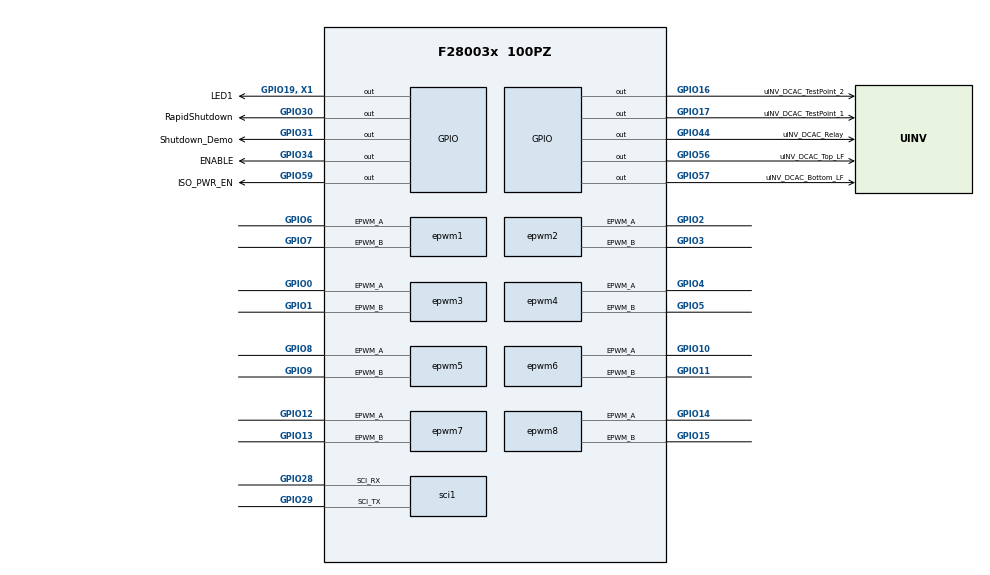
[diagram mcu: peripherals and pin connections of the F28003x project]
/**
 * @cliArgs --device "F28003x" --package "100PZ" --part "F28003x_100PZ" --context "system" --product "C2000WARE@5.02.00.00"
 * @versions {"tool":"1.20.0+3562"}
 */

/**
 * Import the modules used in this configuration.
 */
const adc              = scripting.addModule("/driverlib/adc.js", {}, false);
const adc1             = adc.addInstance();
const adc2             = adc.addInstance();
const adc3             = adc.addInstance();
const analog           = scripting.addModule("/driverlib/analog.js", {}, false);
const analog1          = analog.addInstance();
const asysctl          = scripting.addModule("/driverlib/asysctl.js");
const clb              = scripting.addModule("/driverlib/clb.js", {}, false);
const clb1             = clb.addInstance();
const cmpss            = scripting.addModule("/driverlib/cmpss.js", {}, false);
const cmpss1           = cmpss.addInstance();
const cmpss2           = cmpss.addInstance();
const device_support   = scripting.addModule("/driverlib/device_support.js");
const ecap             = scripting.addModule("/driverlib/ecap.js", {}, false);
const ecap1            = ecap.addInstance();
const epwm             = scripting.addModule("/driverlib/epwm.js", {}, false);
const epwm1            = epwm.addInstance();
const epwm2            = epwm.addInstance();
const epwm3            = epwm.addInstance();
const epwm4            = epwm.addInstance();
const epwm5            = epwm.addInstance();
const epwm6            = epwm.addInstance();
const epwm7            = epwm.addInstance();
const epwm8            = epwm.addInstance();
const epwmxbar         = scripting.addModule("/driverlib/epwmxbar.js", {}, false);
const epwmxbar1        = epwmxbar.addInstance();
const epwmxbar2        = epwmxbar.addInstance();
const epwmxbar3        = epwmxbar.addInstance();
const gpio             = scripting.addModule("/driverlib/gpio.js", {}, false);
const gpio1            = gpio.addInstance();
const gpio2            = gpio.addInstance();
const gpio3            = gpio.addInstance();
const gpio4            = gpio.addInstance();
const gpio5            = gpio.addInstance();
const gpio6            = gpio.addInstance();
const gpio7            = gpio.addInstance();
const gpio8            = gpio.addInstance();
const gpio9            = gpio.addInstance();
const gpio10           = gpio.addInstance();
const inputxbar_input  = scripting.addModule("/driverlib/inputxbar_input.js", {}, false);
const inputxbar_input1 = inputxbar_input.addInstance();
const inputxbar_input2 = inputxbar_input.addInstance();
const inputxbar_input3 = inputxbar_input.addInstance();
const inputxbar_input4 = inputxbar_input.addInstance();
const sci              = scripting.addModule("/driverlib/sci.js", {}, false);
const sci1             = sci.addInstance();
const sync             = scripting.addModule("/driverlib/sync.js");
const sysctl           = scripting.addModule("/driverlib/sysctl.js");
const CMD              = scripting.addModule("/utilities/cmd_tool/cmd_syscfg/source/CMD");
const CMD1             = CMD.addInstance();

/**
 * Write custom configuration values to the imported modules.
 */
adc1.$name                       = "ADC_A";
adc1.soc0IndependentNameMode     = true;
adc1.soc0Channel                 = "ADC_CH_ADCIN6";
adc1.soc0InputCapacitance        = 300;
adc1.soc0InputResistance         = 300;
adc1.soc0UseCalculatedSampleTime = true;
adc1.soc1InputCapacitance        = 300;
adc1.soc1InputResistance         = 300;
adc1.soc1UseCalculatedSampleTime = true;
adc1.soc1IndependentNameMode     = true;
adc1.soc2IndependentNameMode     = true;
adc1.soc3IndependentNameMode     = true;
adc1.soc2InputCapacitance        = 300;
adc1.soc2InputResistance         = 300;
adc1.soc3InputCapacitance        = 300;
adc1.soc3InputResistance         = 300;
adc1.soc3UseCalculatedSampleTime = true;
adc1.soc2UseCalculatedSampleTime = true;
adc1.interruptPulseMode          = "ADC_PULSE_END_OF_CONV";
adc1.soc4IndependentNameMode     = true;
adc1.interrupt1SOCSource         = "ADC_SOC_NUMBER3";
adc1.soc0Name                    = "SOC_BOOST1_CS1";
adc1.soc0Trigger                 = "ADC_TRIGGER_EPWM4_SOCA";
adc1.soc1Name                    = "SOC_BOOST1_CS2";
adc1.soc1Channel                 = "ADC_CH_ADCIN6";
adc1.soc1Trigger                 = "ADC_TRIGGER_EPWM4_SOCB";
adc1.soc2Name                    = "SOC_BOOST1_VS";
adc1.soc2Channel                 = "ADC_CH_ADCIN5";
adc1.soc2Trigger                 = "ADC_TRIGGER_EPWM4_SOCB";
adc1.soc3Name                    = "SOC_BOOST2_CS1";
adc1.soc3Channel                 = "ADC_CH_ADCIN4";
adc1.soc3Trigger                 = "ADC_TRIGGER_EPWM2_SOCA";
adc1.enabledSOCs                 = ["ADC_SOC_NUMBER0","ADC_SOC_NUMBER1","ADC_SOC_NUMBER2","ADC_SOC_NUMBER3","ADC_SOC_NUMBER4","ADC_SOC_NUMBER5"];
adc1.soc4Name                    = "SOC_BOOST2_CS2";
adc1.soc4Channel                 = "ADC_CH_ADCIN4";
adc1.soc4Trigger                 = "ADC_TRIGGER_EPWM2_SOCB";
adc1.soc4UseCalculatedSampleTime = true;
adc1.soc4InputResistance         = 100;
adc1.soc4InputCapacitance        = 100;
adc1.soc4SampleWindow            = 12;
adc1.soc3SampleWindow            = 12;
adc1.soc2SampleWindow            = 12;
adc1.soc1SampleWindow            = 12;
adc1.soc0SampleWindow            = 12;
adc1.soc5Name                    = "SOC_BOOST2_VS";
adc1.soc5SampleWindow            = 12;
adc1.soc5Channel                 = "ADC_CH_ADCIN2";
adc1.soc5Trigger                 = "ADC_TRIGGER_EPWM2_SOCB";
adc1.soc5IndependentNameMode     = true;
adc1.adcClockPrescaler           = "ADC_CLK_DIV_2_0";

adc2.$name                       = "ADC_B";
adc2.adcBase                     = "ADCB_BASE";
adc2.soc0IndependentNameMode     = true;
adc2.soc1IndependentNameMode     = true;
adc2.soc0Channel                 = "ADC_CH_ADCIN3";
adc2.soc0InputCapacitance        = 300;
adc2.soc0InputResistance         = 300;
adc2.soc0UseCalculatedSampleTime = true;
adc2.soc1InputCapacitance        = 300;
adc2.soc1InputResistance         = 300;
adc2.soc1UseCalculatedSampleTime = true;
adc2.soc2IndependentNameMode     = true;
adc2.soc3IndependentNameMode     = true;
adc2.soc2InputCapacitance        = 300;
adc2.soc2InputResistance         = 300;
adc2.soc2UseCalculatedSampleTime = true;
adc2.soc3InputCapacitance        = 300;
adc2.soc3InputResistance         = 300;
adc2.soc3UseCalculatedSampleTime = true;
adc2.soc4IndependentNameMode     = true;
adc2.soc4InputResistance         = 300;
adc2.soc4UseCalculatedSampleTime = true;
adc2.soc4InputCapacitance        = 300;
adc2.soc5IndependentNameMode     = true;
adc2.soc5InputCapacitance        = 100000;
adc2.soc5InputResistance         = 300;
adc2.soc5UseCalculatedSampleTime = true;
adc2.interruptPulseMode          = "ADC_PULSE_END_OF_CONV";
adc2.soc0Name                    = "SOC_BOOST3_CS1";
adc2.soc0Trigger                 = "ADC_TRIGGER_EPWM1_SOCA";
adc2.soc0SampleWindow            = 12;
adc2.soc1Name                    = "SOC_BOOST3_CS2";
adc2.soc1Channel                 = "ADC_CH_ADCIN3";
adc2.soc1Trigger                 = "ADC_TRIGGER_EPWM1_SOCB";
adc2.soc1SampleWindow            = 12;
adc2.soc2Name                    = "SOC_BOOST3_VS";
adc2.soc2Channel                 = "ADC_CH_ADCIN2";
adc2.soc2Trigger                 = "ADC_TRIGGER_EPWM1_SOCB";
adc2.soc2SampleWindow            = 12;
adc2.soc3Name                    = "SOC_BOOST4_CS1";
adc2.soc3Trigger                 = "ADC_TRIGGER_EPWM3_SOCA";
adc2.soc3SampleWindow            = 12;
adc2.soc3Channel                 = "ADC_CH_ADCIN12";
adc2.soc4Name                    = "SOC_BOOST4_CS2";
adc2.soc4Channel                 = "ADC_CH_ADCIN12";
adc2.soc4Trigger                 = "ADC_TRIGGER_EPWM3_SOCB";
adc2.soc4SampleWindow            = 12;
adc2.soc5Name                    = "SOC_BOOST4_VS";
adc2.soc5Channel                 = "ADC_CH_ADCIN4";
adc2.soc5Trigger                 = "ADC_TRIGGER_EPWM3_SOCB";
adc2.soc5SampleWindow            = 12;
adc2.enabledSOCs                 = ["ADC_SOC_NUMBER0","ADC_SOC_NUMBER1","ADC_SOC_NUMBER2","ADC_SOC_NUMBER3","ADC_SOC_NUMBER4","ADC_SOC_NUMBER5","ADC_SOC_NUMBER6","ADC_SOC_NUMBER7"];
adc2.soc6Name                    = "SOC_LLC_VS";
adc2.soc6Channel                 = "ADC_CH_ADCIN5";
adc2.soc6Trigger                 = "ADC_TRIGGER_EPWM3_SOCB";
adc2.soc6SampleWindow            = 12;
adc2.soc7Name                    = "SOC_IREF";
adc2.soc7Channel                 = "ADC_CH_ADCIN11";
adc2.soc7Trigger                 = "ADC_TRIGGER_EPWM3_SOCA";
adc2.soc7SampleWindow            = 12;
adc2.soc7IndependentNameMode     = true;
adc2.soc6IndependentNameMode     = true;
adc2.enabledInts                 = ["ADC_INT_NUMBER1"];
adc2.enableInterrupt1            = true;
adc2.interrupt1SOCSource         = "ADC_SOC_NUMBER6";
adc2.registerInterrupts          = ["1"];
adc2.adcClockPrescaler           = "ADC_CLK_DIV_2_0";
adc2.adcInt1.enableInterrupt     = true;
adc2.adcInt1.interruptHandler    = "ISR2";

adc3.$name                       = "ADC_C";
adc3.adcBase                     = "ADCC_BASE";
adc3.soc0IndependentNameMode     = true;
adc3.soc0InputCapacitance        = 300;
adc3.soc0InputResistance         = 300;
adc3.soc0UseCalculatedSampleTime = true;
adc3.soc1IndependentNameMode     = true;
adc3.soc1InputCapacitance        = 300;
adc3.soc1InputResistance         = 300;
adc3.soc1UseCalculatedSampleTime = true;
adc3.soc2IndependentNameMode     = true;
adc3.soc2InputCapacitance        = 300;
adc3.soc2InputResistance         = 300;
adc3.soc2UseCalculatedSampleTime = true;
adc3.soc3IndependentNameMode     = true;
adc3.soc3InputCapacitance        = 300;
adc3.soc3InputResistance         = 300;
adc3.soc3UseCalculatedSampleTime = true;
adc3.soc4IndependentNameMode     = true;
adc3.soc4InputResistance         = 10000;
adc3.soc4InputCapacitance        = 100000;
adc3.enableInterrupt1            = true;
adc3.soc5IndependentNameMode     = true;
adc3.soc5SampleWindow            = 100;
adc3.interrupt1SOCSource         = "ADC_SOC_NUMBER5";
adc3.soc0Trigger                 = "ADC_TRIGGER_EPWM8_SOCA";
adc3.soc0SampleWindow            = 12;
adc3.soc1SampleWindow            = 12;
adc3.soc2SampleWindow            = 12;
adc3.soc1Trigger                 = "ADC_TRIGGER_EPWM8_SOCA";
adc3.soc2Trigger                 = "ADC_TRIGGER_EPWM8_SOCB";
adc3.soc3Trigger                 = "ADC_TRIGGER_EPWM8_SOCB";
adc3.soc3SampleWindow            = 12;
adc3.soc4Trigger                 = "ADC_TRIGGER_EPWM8_SOCA";
adc3.soc4SampleWindow            = 12;
adc3.soc5Trigger                 = "ADC_TRIGGER_EPWM8_SOCB";
adc3.enabledSOCs                 = ["ADC_SOC_NUMBER0","ADC_SOC_NUMBER1","ADC_SOC_NUMBER2","ADC_SOC_NUMBER3","ADC_SOC_NUMBER4","ADC_SOC_NUMBER5","ADC_SOC_NUMBER6"];
adc3.soc6Name                    = "SOC_TEMP";
adc3.soc6IndependentNameMode     = true;
adc3.soc6Channel                 = "ADC_CH_ADCIN1";
adc3.soc6SampleWindow            = 12;
adc3.interrupt2SOCSource         = "ADC_SOC_NUMBER4";
adc3.enableInterrupt2            = true;
adc3.interruptPulseMode          = "ADC_PULSE_END_OF_CONV";
adc3.soc0Channel                 = "ADC_CH_ADCIN5";
adc3.soc1Channel                 = "ADC_CH_ADCIN3";
adc3.soc2Channel                 = "ADC_CH_ADCIN5";
adc3.soc3Channel                 = "ADC_CH_ADCIN3";
adc3.soc0Name                    = "SOC_DC_BUS_CS1";
adc3.soc1Name                    = "SOC_AC_CS1";
adc3.soc2Name                    = "SOC_DC_BUS_CS2";
adc3.soc3Name                    = "SOC_AC_CS2";
adc3.soc4Name                    = "SOC_AC_VS";
adc3.soc5Name                    = "SOC_DC_BUS_VS";
adc3.enabledInts                 = ["ADC_INT_NUMBER1"];
adc3.registerInterrupts          = ["1"];
adc3.adcClockPrescaler           = "ADC_CLK_DIV_2_0";
adc3.soc5Channel                 = "ADC_CH_ADCIN11";
adc3.soc4Channel                 = "ADC_CH_ADCIN7";
adc3.adcInt1.enableInterrupt     = true;
adc3.adcInt1.interruptHandler    = "ISR1";

asysctl.enableTemperatureSensor = true;
asysctl.analogReference         = "INTERNAL";
asysctl.analogReferenceVoltage  = "1P65";

clb1.$name     = "myCLB0";
clb1.enableCLB = true;

cmpss1.cmpssBase           = "CMPSS4_BASE";
cmpss1.enableModule        = true;
cmpss1.asysCMPHPMXSELValue = "1";
cmpss1.asysCMPLPMXSELValue = "1";
cmpss1.lowCompInvert       = true;
cmpss1.dacValHigh          = 3500;
cmpss1.dacValLow           = 500;
cmpss1.$name               = "myCMPSS";

cmpss2.$name               = "CMPSS_SR";
cmpss2.cmpssBase           = "CMPSS2_BASE";
cmpss2.asysCMPHPMXSELValue = "2";
cmpss2.asysCMPLPMXSELValue = "2";
cmpss2.enableModule        = true;
cmpss2.enableBlanking      = true;
cmpss2.configBlanking      = "7";
cmpss2.configLatchLow      = true;
cmpss2.configLatchHigh     = true;
cmpss2.latchResetHigh      = true;
cmpss2.latchResetLow       = true;
cmpss2.lowCompInvert       = true;
cmpss2.initFilterHigh      = true;
cmpss2.initFilterLow       = true;
cmpss2.lowCTRIP            = "CMPSS_TRIP_FILTER";
cmpss2.highCTRIP           = "CMPSS_TRIP_FILTER";
cmpss2.dacValHigh          = 2000;
cmpss2.dacValLow           = 2096;
cmpss2.sampleWindowLow     = 7;
cmpss2.thresholdLow        = 5;
cmpss2.sampleWindowHigh    = 7;
cmpss2.thresholdHigh       = 5;

cmpss1.analog            = analog1;
analog1.$name            = "myANALOGPinMux0";
adc1.analog              = analog1;
adc3.analog              = analog1;
adc2.analog              = analog1;
analog1.useCase          = "CUSTOM";
cmpss2.analog            = analog1;
analog1.useInterfacePins = ["A0/B15/C15/DACA_OUT","A1/B7/DACB_OUT","A10/B1/C10","A12, C5","A2/B6/C9","A3, C7/B9","A4/B8","A5","A6","A9","B0/C11","B11","B2/C6","B3/VDAC","B4/C8","B5","C1","C2/B12","C3/A7"];

ecap1.$name                  = "myECAP0";
ecap1.interruptSourceCapture = ["ECAP_ISR_SOURCE_CAPTURE_EVENT_4"];
ecap1.eventStop              = "ECAP_EVENT_4";
ecap1.resetCounters          = true;
ecap1.eventOnePolarity       = "ECAP_EVNT_FALLING_EDGE";
ecap1.eventThreePolarity     = "ECAP_EVNT_FALLING_EDGE";
ecap1.counterResetOnEvent    = ["ECAP_EVENT_4"];
ecap1.enableLoadCounter      = true;
ecap1.captureMode            = "ECAP_ONE_SHOT_CAPTURE_MODE";
ecap1.ecapInput              = "ECAP_INPUT_INPUTXBAR1";

epwm1.$name                                                      = "BOOST1";
epwm1.epwmDeadband_enableFED                                     = true;
epwm1.epwmDeadband_enableRED                                     = true;
epwm1.epwmDeadband_polarityFED                                   = "EPWM_DB_POLARITY_ACTIVE_LOW";
epwm1.epwmActionQualifier_EPWM_AQ_OUTPUT_A_ON_TIMEBASE_UP_CMPA   = "EPWM_AQ_OUTPUT_LOW";
epwm1.epwmTimebase_hsClockDiv                                    = "EPWM_HSCLOCK_DIVIDER_1";
epwm1.epwmTimebase_emulationMode                                 = "EPWM_EMULATION_FREE_RUN";
epwm1.epwmEventTrigger_EPWM_SOC_B_triggerEnable                  = true;
epwm1.epwmEventTrigger_EPWM_SOC_A_triggerEnable                  = true;
epwm1.epwmActionQualifier_EPWM_AQ_OUTPUT_A_ON_TIMEBASE_ZERO      = "EPWM_AQ_OUTPUT_HIGH";
epwm1.epwmActionQualifier_EPWM_AQ_OUTPUT_B_ON_TIMEBASE_ZERO      = "EPWM_AQ_OUTPUT_HIGH";
epwm1.epwmDeadband_inputFED                                      = "EPWM_DB_INPUT_EPWMB";
epwm1.epwmTripZone_EPWM_TZ_ACTION_EVENT_TZA                      = "EPWM_TZ_ACTION_LOW";
epwm1.epwmTripZone_EPWM_TZ_ACTION_EVENT_TZB                      = "EPWM_TZ_ACTION_LOW";
epwm1.epwmTripZone_EPWM_TZ_ACTION_EVENT_DCAEVT1                  = "EPWM_TZ_ACTION_LOW";
epwm1.epwmTripZone_EPWM_TZ_ACTION_EVENT_DCAEVT2                  = "EPWM_TZ_ACTION_LOW";
epwm1.epwmTripZone_EPWM_TZ_ACTION_EVENT_DCBEVT1                  = "EPWM_TZ_ACTION_LOW";
epwm1.epwmTripZone_EPWM_TZ_ACTION_EVENT_DCBEVT2                  = "EPWM_TZ_ACTION_LOW";
epwm1.epwmEventTrigger_EPWM_SOC_A_triggerEventPrescalar          = "6";
epwm1.epwmEventTrigger_EPWM_SOC_B_triggerEventPrescalar          = "6";
epwm1.epwmDeadband_delayRED                                      = 2;
epwm1.epwmDeadband_delayFED                                      = 2;
epwm1.epwmTimebase_phaseEnable                                   = true;
epwm1.epwmTimebase_syncOutPulseMode                              = ["EPWM_SYNC_OUT_PULSE_ON_SOFTWARE"];
epwm1.epwmTimebase_counterMode                                   = "EPWM_COUNTER_MODE_UP_DOWN";
epwm1.epwmTimebase_phaseShift                                    = 2;
epwm1.epwmTimebase_period                                        = 250;
epwm1.epwmEventTrigger_EPWM_SOC_A_triggerSource                  = "EPWM_SOC_TBCTR_ZERO";
epwm1.epwmEventTrigger_EPWM_SOC_B_triggerSource                  = "EPWM_SOC_TBCTR_PERIOD";
epwm1.epwmActionQualifier_EPWM_AQ_OUTPUT_A_ON_TIMEBASE_PERIOD    = "EPWM_AQ_OUTPUT_LOW";
epwm1.epwmActionQualifier_EPWM_AQ_OUTPUT_A_ON_TIMEBASE_DOWN_CMPA = "EPWM_AQ_OUTPUT_HIGH";
epwm1.epwmActionQualifier_EPWM_AQ_OUTPUT_B_ON_TIMEBASE_PERIOD    = "EPWM_AQ_OUTPUT_LOW";
epwm1.epwmActionQualifier_EPWM_AQ_OUTPUT_B_ON_TIMEBASE_UP_CMPB   = "EPWM_AQ_OUTPUT_LOW";
epwm1.epwmActionQualifier_EPWM_AQ_OUTPUT_B_ON_TIMEBASE_DOWN_CMPB = "EPWM_AQ_OUTPUT_HIGH";
epwm1.epwmTimebase_counterModeAfterSync                          = "EPWM_COUNT_MODE_UP_AFTER_SYNC";
epwm1.epwmTimebase_syncInPulseSource                             = "EPWM_SYNC_IN_PULSE_SRC_SYNCOUT_EPWM8";
epwm1.epwm.epwm_aPin.$assign                                     = "GPIO6";
epwm1.epwm.epwm_bPin.$assign                                     = "GPIO7";

epwm2.$name                                                      = "BOOST2";
epwm2.epwmDeadband_enableFED                                     = true;
epwm2.epwmDeadband_enableRED                                     = true;
epwm2.epwmDeadband_polarityFED                                   = "EPWM_DB_POLARITY_ACTIVE_LOW";
epwm2.epwmActionQualifier_EPWM_AQ_OUTPUT_A_ON_TIMEBASE_UP_CMPA   = "EPWM_AQ_OUTPUT_LOW";
epwm2.epwmTimebase_hsClockDiv                                    = "EPWM_HSCLOCK_DIVIDER_1";
epwm2.epwmTimebase_emulationMode                                 = "EPWM_EMULATION_FREE_RUN";
epwm2.epwmEventTrigger_EPWM_SOC_B_triggerEnable                  = true;
epwm2.epwmEventTrigger_EPWM_SOC_A_triggerEnable                  = true;
epwm2.epwmActionQualifier_EPWM_AQ_OUTPUT_A_ON_TIMEBASE_ZERO      = "EPWM_AQ_OUTPUT_HIGH";
epwm2.epwmActionQualifier_EPWM_AQ_OUTPUT_B_ON_TIMEBASE_ZERO      = "EPWM_AQ_OUTPUT_HIGH";
epwm2.epwmDeadband_inputFED                                      = "EPWM_DB_INPUT_EPWMB";
epwm2.epwmTripZone_EPWM_TZ_ACTION_EVENT_TZA                      = "EPWM_TZ_ACTION_LOW";
epwm2.epwmTripZone_EPWM_TZ_ACTION_EVENT_TZB                      = "EPWM_TZ_ACTION_LOW";
epwm2.epwmTripZone_EPWM_TZ_ACTION_EVENT_DCAEVT1                  = "EPWM_TZ_ACTION_LOW";
epwm2.epwmTripZone_EPWM_TZ_ACTION_EVENT_DCAEVT2                  = "EPWM_TZ_ACTION_LOW";
epwm2.epwmTripZone_EPWM_TZ_ACTION_EVENT_DCBEVT1                  = "EPWM_TZ_ACTION_LOW";
epwm2.epwmTripZone_EPWM_TZ_ACTION_EVENT_DCBEVT2                  = "EPWM_TZ_ACTION_LOW";
epwm2.epwmEventTrigger_EPWM_SOC_B_triggerEventPrescalar          = "6";
epwm2.epwmEventTrigger_EPWM_SOC_A_triggerEventPrescalar          = "6";
epwm2.epwmDeadband_delayRED                                      = 2;
epwm2.epwmDeadband_delayFED                                      = 2;
epwm2.epwmTimebase_phaseEnable                                   = true;
epwm2.epwmTimebase_period                                        = 250;
epwm2.epwmTimebase_phaseShift                                    = 2;
epwm2.epwmTimebase_counterMode                                   = "EPWM_COUNTER_MODE_UP_DOWN";
epwm2.epwmActionQualifier_EPWM_AQ_OUTPUT_A_ON_TIMEBASE_PERIOD    = "EPWM_AQ_OUTPUT_LOW";
epwm2.epwmActionQualifier_EPWM_AQ_OUTPUT_A_ON_TIMEBASE_DOWN_CMPA = "EPWM_AQ_OUTPUT_HIGH";
epwm2.epwmActionQualifier_EPWM_AQ_OUTPUT_B_ON_TIMEBASE_PERIOD    = "EPWM_AQ_OUTPUT_LOW";
epwm2.epwmActionQualifier_EPWM_AQ_OUTPUT_B_ON_TIMEBASE_UP_CMPB   = "EPWM_AQ_OUTPUT_LOW";
epwm2.epwmActionQualifier_EPWM_AQ_OUTPUT_B_ON_TIMEBASE_DOWN_CMPB = "EPWM_AQ_OUTPUT_HIGH";
epwm2.epwmEventTrigger_EPWM_SOC_A_triggerSource                  = "EPWM_SOC_TBCTR_ZERO";
epwm2.epwmEventTrigger_EPWM_SOC_B_triggerSource                  = "EPWM_SOC_TBCTR_PERIOD";
epwm2.epwmTimebase_counterModeAfterSync                          = "EPWM_COUNT_MODE_UP_AFTER_SYNC";
epwm2.epwmTimebase_syncInPulseSource                             = "EPWM_SYNC_IN_PULSE_SRC_SYNCOUT_EPWM8";
epwm2.epwm.$assign                                               = "EPWM2";
epwm2.epwm.epwm_aPin.$assign                                     = "GPIO2";
epwm2.epwm.epwm_bPin.$assign                                     = "GPIO3";

epwm3.$name                                                      = "BOOST3";
epwm3.epwmDeadband_enableFED                                     = true;
epwm3.epwmDeadband_enableRED                                     = true;
epwm3.epwmDeadband_polarityFED                                   = "EPWM_DB_POLARITY_ACTIVE_LOW";
epwm3.epwmActionQualifier_EPWM_AQ_OUTPUT_A_ON_TIMEBASE_UP_CMPA   = "EPWM_AQ_OUTPUT_LOW";
epwm3.epwmTimebase_hsClockDiv                                    = "EPWM_HSCLOCK_DIVIDER_1";
epwm3.epwmTimebase_emulationMode                                 = "EPWM_EMULATION_FREE_RUN";
epwm3.epwmEventTrigger_EPWM_SOC_B_triggerEnable                  = true;
epwm3.epwmEventTrigger_EPWM_SOC_A_triggerEnable                  = true;
epwm3.epwmActionQualifier_EPWM_AQ_OUTPUT_A_ON_TIMEBASE_ZERO      = "EPWM_AQ_OUTPUT_HIGH";
epwm3.epwmActionQualifier_EPWM_AQ_OUTPUT_B_ON_TIMEBASE_ZERO      = "EPWM_AQ_OUTPUT_HIGH";
epwm3.epwmDeadband_inputFED                                      = "EPWM_DB_INPUT_EPWMB";
epwm3.epwmTripZone_EPWM_TZ_ACTION_EVENT_TZA                      = "EPWM_TZ_ACTION_LOW";
epwm3.epwmTripZone_EPWM_TZ_ACTION_EVENT_TZB                      = "EPWM_TZ_ACTION_LOW";
epwm3.epwmTripZone_EPWM_TZ_ACTION_EVENT_DCAEVT1                  = "EPWM_TZ_ACTION_LOW";
epwm3.epwmTripZone_EPWM_TZ_ACTION_EVENT_DCAEVT2                  = "EPWM_TZ_ACTION_LOW";
epwm3.epwmTripZone_EPWM_TZ_ACTION_EVENT_DCBEVT1                  = "EPWM_TZ_ACTION_LOW";
epwm3.epwmTripZone_EPWM_TZ_ACTION_EVENT_DCBEVT2                  = "EPWM_TZ_ACTION_LOW";
epwm3.epwmEventTrigger_EPWM_SOC_B_triggerEventPrescalar          = "6";
epwm3.epwmEventTrigger_EPWM_SOC_A_triggerEventPrescalar          = "6";
epwm3.epwmDeadband_delayRED                                      = 2;
epwm3.epwmDeadband_delayFED                                      = 2;
epwm3.epwmTimebase_phaseEnable                                   = true;
epwm3.epwmTimebase_period                                        = 250;
epwm3.epwmTimebase_phaseShift                                    = 2;
epwm3.epwmTimebase_counterMode                                   = "EPWM_COUNTER_MODE_UP_DOWN";
epwm3.epwmActionQualifier_EPWM_AQ_OUTPUT_A_ON_TIMEBASE_PERIOD    = "EPWM_AQ_OUTPUT_LOW";
epwm3.epwmActionQualifier_EPWM_AQ_OUTPUT_A_ON_TIMEBASE_DOWN_CMPA = "EPWM_AQ_OUTPUT_HIGH";
epwm3.epwmActionQualifier_EPWM_AQ_OUTPUT_B_ON_TIMEBASE_PERIOD    = "EPWM_AQ_OUTPUT_LOW";
epwm3.epwmActionQualifier_EPWM_AQ_OUTPUT_B_ON_TIMEBASE_UP_CMPB   = "EPWM_AQ_OUTPUT_LOW";
epwm3.epwmActionQualifier_EPWM_AQ_OUTPUT_B_ON_TIMEBASE_DOWN_CMPB = "EPWM_AQ_OUTPUT_HIGH";
epwm3.epwmEventTrigger_EPWM_SOC_A_triggerSource                  = "EPWM_SOC_TBCTR_ZERO";
epwm3.epwmEventTrigger_EPWM_SOC_B_triggerSource                  = "EPWM_SOC_TBCTR_PERIOD";
epwm3.epwmTimebase_syncInPulseSource                             = "EPWM_SYNC_IN_PULSE_SRC_SYNCOUT_EPWM8";
epwm3.epwm.$assign                                               = "EPWM1";
epwm3.epwm.epwm_aPin.$assign                                     = "GPIO0";
epwm3.epwm.epwm_bPin.$assign                                     = "GPIO1";

epwm4.$name                                                      = "BOOST4";
epwm4.epwmDeadband_enableFED                                     = true;
epwm4.epwmDeadband_enableRED                                     = true;
epwm4.epwmDeadband_polarityFED                                   = "EPWM_DB_POLARITY_ACTIVE_LOW";
epwm4.epwmActionQualifier_EPWM_AQ_OUTPUT_A_ON_TIMEBASE_UP_CMPA   = "EPWM_AQ_OUTPUT_LOW";
epwm4.epwmTimebase_hsClockDiv                                    = "EPWM_HSCLOCK_DIVIDER_1";
epwm4.epwmTimebase_emulationMode                                 = "EPWM_EMULATION_FREE_RUN";
epwm4.epwmEventTrigger_EPWM_SOC_B_triggerEnable                  = true;
epwm4.epwmEventTrigger_EPWM_SOC_A_triggerEnable                  = true;
epwm4.epwmActionQualifier_EPWM_AQ_OUTPUT_A_ON_TIMEBASE_ZERO      = "EPWM_AQ_OUTPUT_HIGH";
epwm4.epwmActionQualifier_EPWM_AQ_OUTPUT_B_ON_TIMEBASE_ZERO      = "EPWM_AQ_OUTPUT_HIGH";
epwm4.epwmDeadband_inputFED                                      = "EPWM_DB_INPUT_EPWMB";
epwm4.epwmTripZone_EPWM_TZ_ACTION_EVENT_TZA                      = "EPWM_TZ_ACTION_LOW";
epwm4.epwmTripZone_EPWM_TZ_ACTION_EVENT_TZB                      = "EPWM_TZ_ACTION_LOW";
epwm4.epwmTripZone_EPWM_TZ_ACTION_EVENT_DCAEVT1                  = "EPWM_TZ_ACTION_LOW";
epwm4.epwmTripZone_EPWM_TZ_ACTION_EVENT_DCAEVT2                  = "EPWM_TZ_ACTION_LOW";
epwm4.epwmTripZone_EPWM_TZ_ACTION_EVENT_DCBEVT1                  = "EPWM_TZ_ACTION_LOW";
epwm4.epwmTripZone_EPWM_TZ_ACTION_EVENT_DCBEVT2                  = "EPWM_TZ_ACTION_LOW";
epwm4.epwmEventTrigger_EPWM_SOC_A_triggerEventPrescalar          = "6";
epwm4.epwmEventTrigger_EPWM_SOC_B_triggerEventPrescalar          = "6";
epwm4.epwmDeadband_delayRED                                      = 2;
epwm4.epwmDeadband_delayFED                                      = 2;
epwm4.epwmTimebase_phaseEnable                                   = true;
epwm4.epwmTimebase_period                                        = 250;
epwm4.epwmTimebase_counterMode                                   = "EPWM_COUNTER_MODE_UP_DOWN";
epwm4.epwmTimebase_phaseShift                                    = 2;
epwm4.epwmActionQualifier_EPWM_AQ_OUTPUT_A_ON_TIMEBASE_PERIOD    = "EPWM_AQ_OUTPUT_LOW";
epwm4.epwmActionQualifier_EPWM_AQ_OUTPUT_A_ON_TIMEBASE_DOWN_CMPA = "EPWM_AQ_OUTPUT_HIGH";
epwm4.epwmActionQualifier_EPWM_AQ_OUTPUT_B_ON_TIMEBASE_PERIOD    = "EPWM_AQ_OUTPUT_LOW";
epwm4.epwmActionQualifier_EPWM_AQ_OUTPUT_B_ON_TIMEBASE_UP_CMPB   = "EPWM_AQ_OUTPUT_LOW";
epwm4.epwmActionQualifier_EPWM_AQ_OUTPUT_B_ON_TIMEBASE_DOWN_CMPB = "EPWM_AQ_OUTPUT_HIGH";
epwm4.epwmEventTrigger_EPWM_SOC_A_triggerSource                  = "EPWM_SOC_TBCTR_ZERO";
epwm4.epwmEventTrigger_EPWM_SOC_B_triggerSource                  = "EPWM_SOC_TBCTR_PERIOD";
epwm4.epwmTimebase_syncInPulseSource                             = "EPWM_SYNC_IN_PULSE_SRC_SYNCOUT_EPWM8";
epwm4.epwm.$assign                                               = "EPWM3";
epwm4.epwm.epwm_aPin.$assign                                     = "GPIO4";
epwm4.epwm.epwm_bPin.$assign                                     = "GPIO5";

epwm5.$name                                                      = "LLC1";
epwm5.copyUse                                                    = true;
epwm5.copyFrom                                                   = "BOOST1";
epwm5.epwmActionQualifier_EPWM_AQ_OUTPUT_A_ON_TIMEBASE_UP_CMPA   = "EPWM_AQ_OUTPUT_LOW";
epwm5.epwmDeadband_polarityFED                                   = "EPWM_DB_POLARITY_ACTIVE_LOW";
epwm5.epwmDeadband_enableRED                                     = true;
epwm5.epwmDeadband_enableFED                                     = true;
epwm5.epwmTimebase_hsClockDiv                                    = "EPWM_HSCLOCK_DIVIDER_1";
epwm5.epwmActionQualifier_EPWM_AQ_OUTPUT_A_ON_TIMEBASE_ZERO      = "EPWM_AQ_OUTPUT_HIGH";
epwm5.epwmTimebase_emulationMode                                 = "EPWM_EMULATION_FREE_RUN";
epwm5.epwmTimebase_syncOutPulseMode                              = ["EPWM_SYNC_OUT_PULSE_ON_CNTR_ZERO"];
epwm5.epwmDeadband_delayRED                                      = 3;
epwm5.epwmDeadband_delayFED                                      = 3;
epwm5.epwmTimebase_syncInPulseSource                             = "EPWM_SYNC_IN_PULSE_SRC_DISABLE";
epwm5.epwmTimebase_counterMode                                   = "EPWM_COUNTER_MODE_UP_DOWN";
epwm5.epwmActionQualifier_EPWM_AQ_OUTPUT_A_ON_TIMEBASE_DOWN_CMPA = "EPWM_AQ_OUTPUT_HIGH";
epwm5.epwmActionQualifier_EPWM_AQ_OUTPUT_A_ON_TIMEBASE_PERIOD    = "EPWM_AQ_OUTPUT_LOW";
epwm5.epwmTripZone_EPWM_TZ_ACTION_EVENT_TZA                      = "EPWM_TZ_ACTION_LOW";
epwm5.epwmTripZone_EPWM_TZ_ACTION_EVENT_TZB                      = "EPWM_TZ_ACTION_LOW";
epwm5.epwmTripZone_EPWM_TZ_ACTION_EVENT_DCAEVT1                  = "EPWM_TZ_ACTION_LOW";
epwm5.epwmTripZone_EPWM_TZ_ACTION_EVENT_DCAEVT2                  = "EPWM_TZ_ACTION_LOW";
epwm5.epwmTripZone_EPWM_TZ_ACTION_EVENT_DCBEVT1                  = "EPWM_TZ_ACTION_LOW";
epwm5.epwmTripZone_EPWM_TZ_ACTION_EVENT_DCBEVT2                  = "EPWM_TZ_ACTION_LOW";
epwm5.epwmTimebase_period                                        = 120;
epwm5.epwm.$assign                                               = "EPWM5";
epwm5.epwm.epwm_aPin.$assign                                     = "GPIO8";
epwm5.epwm.epwm_bPin.$assign                                     = "GPIO9";

epwm6.$name                                                      = "LLC2";
epwm6.copyUse                                                    = true;
epwm6.copyFrom                                                   = "LLC1";
epwm6.epwmDeadband_polarityFED                                   = "EPWM_DB_POLARITY_ACTIVE_LOW";
epwm6.epwmDeadband_enableRED                                     = true;
epwm6.epwmDeadband_enableFED                                     = true;
epwm6.epwmTimebase_hsClockDiv                                    = "EPWM_HSCLOCK_DIVIDER_1";
epwm6.epwmTimebase_phaseEnable                                   = true;
epwm6.epwmActionQualifier_EPWM_AQ_OUTPUT_A_ON_TIMEBASE_ZERO      = "EPWM_AQ_OUTPUT_HIGH";
epwm6.epwmActionQualifier_EPWM_AQ_OUTPUT_A_ON_TIMEBASE_UP_CMPA   = "EPWM_AQ_OUTPUT_LOW";
epwm6.epwmTimebase_emulationMode                                 = "EPWM_EMULATION_FREE_RUN";
epwm6.epwmTimebase_syncInPulseSource                             = "EPWM_SYNC_IN_PULSE_SRC_SYNCOUT_EPWM5";
epwm6.epwmDeadband_delayRED                                      = 3;
epwm6.epwmDeadband_delayFED                                      = 3;
epwm6.epwmTimebase_period                                        = 120;
epwm6.epwmTimebase_counterMode                                   = "EPWM_COUNTER_MODE_UP_DOWN";
epwm6.epwmTimebase_phaseShift                                    = 120;
epwm6.epwmActionQualifier_EPWM_AQ_OUTPUT_A_ON_TIMEBASE_DOWN_CMPA = "EPWM_AQ_OUTPUT_HIGH";
epwm6.epwmActionQualifier_EPWM_AQ_OUTPUT_A_ON_TIMEBASE_PERIOD    = "EPWM_AQ_OUTPUT_LOW";
epwm6.epwmTripZone_EPWM_TZ_ACTION_EVENT_TZA                      = "EPWM_TZ_ACTION_LOW";
epwm6.epwmTripZone_EPWM_TZ_ACTION_EVENT_TZB                      = "EPWM_TZ_ACTION_LOW";
epwm6.epwmTripZone_EPWM_TZ_ACTION_EVENT_DCAEVT1                  = "EPWM_TZ_ACTION_LOW";
epwm6.epwmTripZone_EPWM_TZ_ACTION_EVENT_DCAEVT2                  = "EPWM_TZ_ACTION_LOW";
epwm6.epwmTripZone_EPWM_TZ_ACTION_EVENT_DCBEVT1                  = "EPWM_TZ_ACTION_LOW";
epwm6.epwmTripZone_EPWM_TZ_ACTION_EVENT_DCBEVT2                  = "EPWM_TZ_ACTION_LOW";
epwm6.epwmTimebase_syncOutPulseMode                              = ["EPWM_SYNC_OUT_PULSE_ON_CNTR_ZERO"];
epwm6.epwm.$assign                                               = "EPWM6";
epwm6.epwm.epwm_aPin.$assign                                     = "GPIO10";
epwm6.epwm.epwm_bPin.$assign                                     = "GPIO11";

epwm7.copyUse                                                             = true;
epwm7.copyFrom                                                            = "LLC2";
epwm7.epwmActionQualifier_EPWM_AQ_OUTPUT_A_ON_TIMEBASE_UP_CMPA            = "EPWM_AQ_OUTPUT_LOW";
epwm7.epwmDeadband_enableRED                                              = true;
epwm7.epwmDeadband_enableFED                                              = true;
epwm7.$name                                                               = "LLCSR";
epwm7.epwmTimebase_hsClockDiv                                             = "EPWM_HSCLOCK_DIVIDER_1";
epwm7.epwmTimebase_phaseEnable                                            = true;
epwm7.epwmActionQualifier_EPWM_AQ_OUTPUT_A_ON_TIMEBASE_ZERO               = "EPWM_AQ_OUTPUT_HIGH";
epwm7.epwmTimebase_emulationMode                                          = "EPWM_EMULATION_FREE_RUN";
epwm7.epwmDeadband_delayRED                                               = 12;
epwm7.epwmDeadband_delayFED                                               = 12;
epwm7.epwmTimebase_period                                                 = 120;
epwm7.epwmTimebase_counterMode                                            = "EPWM_COUNTER_MODE_UP_DOWN";
epwm7.epwmCounterCompare_cmpB                                             = 120;
epwm7.epwmDeadband_polarityFED                                            = "EPWM_DB_POLARITY_ACTIVE_LOW";
epwm7.epwmActionQualifier_EPWM_AQ_OUTPUT_A_ON_TIMEBASE_PERIOD             = "EPWM_AQ_OUTPUT_LOW";
epwm7.epwmDigitalCompare_EPWM_DC_MODULE_A_EPWM_DC_EVENT_2_latchMode       = "EPWM_DC_CBC_LATCH_ENABLED";
epwm7.epwmDigitalCompare_EPWM_DC_MODULE_A_EPWM_DC_EVENT_2_latchClearEvent = "EPWM_DC_CBC_LATCH_CLR_ON_CNTR_ZERO_PERIOD";
epwm7.epwmDigitalCompare_EPWM_DC_MODULE_B_EPWM_DC_EVENT_2_latchMode       = "EPWM_DC_CBC_LATCH_ENABLED";
epwm7.epwmDigitalCompare_EPWM_DC_MODULE_B_EPWM_DC_EVENT_2_latchClearEvent = "EPWM_DC_CBC_LATCH_CLR_ON_CNTR_ZERO_PERIOD";
epwm7.epwmDigitalCompare_useBlankingWindow                                = true;
epwm7.epwmDigitalCompare_blankingWindowEvent                              = "EPWM_DC_WINDOW_START_TBCTR_ZERO_PERIOD";
epwm7.epwmDigitalCompare_blankingWindowOffset                             = 116;
epwm7.epwmDigitalCompare_EPWM_DC_TYPE_DCBH                                = "EPWM_DC_TRIP_TRIPIN12";
epwm7.epwmDigitalCompare_EPWM_DC_TYPE_DCAH                                = "EPWM_DC_TRIP_TRIPIN11";
epwm7.epwmActionQualifier_EPWM_AQ_OUTPUT_B_ON_TIMEBASE_ZERO               = "EPWM_AQ_OUTPUT_HIGH";
epwm7.epwmActionQualifier_EPWM_AQ_OUTPUT_B_ON_TIMEBASE_PERIOD             = "EPWM_AQ_OUTPUT_LOW";
epwm7.epwmActionQualifier_EPWM_AQ_OUTPUT_B_ON_TIMEBASE_DOWN_CMPB          = "EPWM_AQ_OUTPUT_HIGH";
epwm7.epwmTimebase_syncInPulseSource                                      = "EPWM_SYNC_IN_PULSE_SRC_SYNCOUT_EPWM6";
epwm7.epwmTimebase_phaseShift                                             = 60;
epwm7.epwmDeadband_inputFED                                               = "EPWM_DB_INPUT_EPWMB";
epwm7.epwmDeadband_outputSwapOutA                                         = true;
epwm7.epwmDeadband_outputSwapOutB                                         = true;
epwm7.epwmDigitalCompare_EPWM_TZ_DC_OUTPUT_A2                             = "EPWM_TZ_EVENT_DCXH_HIGH";
epwm7.epwmDigitalCompare_blankingWindowLength                             = 40;
epwm7.epwmTripZone_cbcPulse                                               = "EPWM_TZ_CBC_PULSE_CLR_CNTR_ZERO_PERIOD";
epwm7.epwmTripZone_EPWM_TZ_ACTION_EVENT_TZA                               = "EPWM_TZ_ACTION_LOW";
epwm7.epwmTripZone_EPWM_TZ_ACTION_EVENT_TZB                               = "EPWM_TZ_ACTION_LOW";
epwm7.epwmTripZone_EPWM_TZ_ACTION_EVENT_DCAEVT1                           = "EPWM_TZ_ACTION_LOW";
epwm7.epwmTripZone_EPWM_TZ_ACTION_EVENT_DCAEVT2                           = "EPWM_TZ_ACTION_LOW";
epwm7.epwmTripZone_EPWM_TZ_ACTION_EVENT_DCBEVT1                           = "EPWM_TZ_ACTION_LOW";
epwm7.epwmTripZone_EPWM_TZ_ACTION_EVENT_DCBEVT2                           = "EPWM_TZ_ACTION_LOW";
epwm7.epwmDigitalCompare_EPWM_DC_TYPE_DCAL                                = "EPWM_DC_TRIP_TRIPIN11";
epwm7.epwmDigitalCompare_EPWM_DC_TYPE_DCBL                                = "EPWM_DC_TRIP_TRIPIN12";
epwm7.epwmDigitalCompare_EPWM_TZ_DC_OUTPUT_B2                             = "EPWM_TZ_EVENT_DCXL_HIGH";
epwm7.epwm.$assign                                                        = "EPWM7";
epwm7.epwm.epwm_aPin.$assign                                              = "GPIO12";
epwm7.epwm.epwm_bPin.$assign                                              = "GPIO13";

epwm8.$name                                                      = "DCAC";
epwm8.copyUse                                                    = true;
epwm8.copyFrom                                                   = "LLC2";
epwm8.epwmActionQualifier_EPWM_AQ_OUTPUT_A_ON_TIMEBASE_UP_CMPA   = "EPWM_AQ_OUTPUT_LOW";
epwm8.epwmActionQualifier_EPWM_AQ_OUTPUT_A_ON_TIMEBASE_DOWN_CMPA = "EPWM_AQ_OUTPUT_HIGH";
epwm8.epwmDeadband_polarityFED                                   = "EPWM_DB_POLARITY_ACTIVE_LOW";
epwm8.epwmDeadband_enableRED                                     = true;
epwm8.epwmDeadband_enableFED                                     = true;
epwm8.epwmTimebase_period                                        = 500;
epwm8.epwmTimebase_counterMode                                   = "EPWM_COUNTER_MODE_UP_DOWN";
epwm8.epwmTimebase_hsClockDiv                                    = "EPWM_HSCLOCK_DIVIDER_1";
epwm8.epwmTimebase_emulationMode                                 = "EPWM_EMULATION_FREE_RUN";
epwm8.epwmDeadband_delayRED                                      = 10;
epwm8.epwmDeadband_delayFED                                      = 10;
epwm8.epwmEventTrigger_EPWM_SOC_B_triggerEnable                  = true;
epwm8.epwmEventTrigger_EPWM_SOC_B_triggerSource                  = "EPWM_SOC_TBCTR_PERIOD";
epwm8.epwmEventTrigger_EPWM_SOC_A_triggerEnable                  = true;
epwm8.epwmEventTrigger_EPWM_SOC_A_triggerSource                  = "EPWM_SOC_TBCTR_ZERO";
epwm8.epwmEventTrigger_EPWM_SOC_A_triggerEventPrescalar          = "6";
epwm8.epwmEventTrigger_EPWM_SOC_B_triggerEventPrescalar          = "6";
epwm8.epwmTripZone_EPWM_TZ_ACTION_EVENT_DCAEVT1                  = "EPWM_TZ_ACTION_LOW";
epwm8.epwmTripZone_EPWM_TZ_ACTION_EVENT_DCBEVT1                  = "EPWM_TZ_ACTION_LOW";
epwm8.epwmTripZone_EPWM_TZ_ACTION_EVENT_TZA                      = "EPWM_TZ_ACTION_LOW";
epwm8.epwmTripZone_EPWM_TZ_ACTION_EVENT_TZB                      = "EPWM_TZ_ACTION_LOW";
epwm8.epwmTripZone_EPWM_TZ_ACTION_EVENT_DCAEVT2                  = "EPWM_TZ_ACTION_LOW";
epwm8.epwmTripZone_EPWM_TZ_ACTION_EVENT_DCBEVT2                  = "EPWM_TZ_ACTION_LOW";
epwm8.epwmEventTrigger_EPWM_SOC_A_triggerEventCountInitEnable    = true;
epwm8.epwmEventTrigger_EPWM_SOC_B_triggerEventCountInitEnable    = true;
epwm8.epwmEventTrigger_EPWM_SOC_B_triggerEventCountInitValue     = "3";
epwm8.epwmEventTrigger_EPWM_SOC_A_triggerEventCountInitForce     = true;
epwm8.epwmEventTrigger_EPWM_SOC_B_triggerEventCountInitForce     = true;
epwm8.epwmEventTrigger_EPWM_SOC_A_triggerEventCountInitValue     = "2";
epwm8.epwmTimebase_syncInPulseSource                             = "EPWM_SYNC_IN_PULSE_SRC_DISABLE";
epwm8.epwmTimebase_syncOutPulseMode                              = ["EPWM_SYNC_OUT_PULSE_ON_CNTR_ZERO"];
epwm8.epwm.$assign                                               = "EPWM8";
epwm8.epwm.epwm_aPin.$assign                                     = "GPIO14";
epwm8.epwm.epwm_bPin.$assign                                     = "GPIO15";

epwmxbar1.$name      = "myEPWMXBAR0";
epwmxbar1.muxesUsed  = ["XBAR_MUX06"];
epwmxbar1.tripInput  = "XBAR_TRIP5";
epwmxbar1.mux6Config = "XBAR_EPWM_MUX06_CMPSS4_CTRIPH_OR_L";

epwmxbar2.$name           = "myEPWMXBAR1_SRTRIP_P";
epwmxbar2.tripInput       = "XBAR_TRIP11";
epwmxbar2.useSourceSelect = true;
epwmxbar2.sourceSignals   = ["CMPSS2_CTRIPL"];

epwmxbar3.useSourceSelect = true;
epwmxbar3.$name           = "myEPWMXBAR1_SRTRIP_N";
epwmxbar3.tripInput       = "XBAR_TRIP12";
epwmxbar3.sourceSignals   = ["CMPSS2_CTRIPH"];

gpio1.direction         = "GPIO_DIR_MODE_OUT";
gpio1.writeInitialValue = true;
gpio1.$name             = "ISO_PWR_EN";
gpio1.gpioPin.$assign   = "GPIO59";

gpio2.$name             = "LED1";
gpio2.direction         = "GPIO_DIR_MODE_OUT";
gpio2.writeInitialValue = true;
gpio2.gpioPin.$assign   = "GPIO19, X1";

gpio3.direction         = "GPIO_DIR_MODE_OUT";
gpio3.writeInitialValue = true;
gpio3.$name             = "uINV_DCAC_Relay";
gpio3.gpioPin.$assign   = "GPIO44";

gpio4.direction       = "GPIO_DIR_MODE_OUT";
gpio4.$name           = "uINV_DCAC_Top_LF";
gpio4.gpioPin.$assign = "GPIO56";

gpio5.direction       = "GPIO_DIR_MODE_OUT";
gpio5.$name           = "uINV_DCAC_Bottom_LF";
gpio5.gpioPin.$assign = "GPIO57";

gpio6.$name             = "ENABLE";
gpio6.direction         = "GPIO_DIR_MODE_OUT";
gpio6.writeInitialValue = true;
gpio6.initialValue      = 1;
gpio6.gpioPin.$assign   = "GPIO34";

gpio7.direction         = "GPIO_DIR_MODE_OUT";
gpio7.writeInitialValue = true;
gpio7.$name             = "uINV_DCAC_TestPoint_1";
gpio7.gpioPin.$assign   = "GPIO17";

gpio8.direction         = "GPIO_DIR_MODE_OUT";
gpio8.writeInitialValue = true;
gpio8.$name             = "uINV_DCAC_TestPoint_2";
gpio8.gpioPin.$assign   = "GPIO16";

gpio9.writeInitialValue = true;
gpio9.$name             = "Shutdown_Demo";
gpio9.gpioPin.$assign   = "GPIO31";

gpio10.writeInitialValue = true;
gpio10.$name             = "RapidShutdown";
gpio10.gpioPin.$assign   = "GPIO30";

inputxbar_input1.$name         = "myINPUTXBARINPUT0";
inputxbar_input1.inputxbarGpio = "GPIO60";

inputxbar_input2.$name          = "myINPUTXBARINPUT1";
inputxbar_input2.inputxbarInput = "XBAR_INPUT2";
inputxbar_input2.inputxbarGpio  = "GPIO58";

inputxbar_input3.$name          = "myINPUTXBARINPUT2";
inputxbar_input3.inputxbarInput = "XBAR_INPUT3";
inputxbar_input3.inputxbarGpio  = "GPIO48";

inputxbar_input4.$name          = "myINPUTXBARINPUT3";
inputxbar_input4.inputxbarInput = "XBAR_INPUT4";
inputxbar_input4.inputxbarGpio  = "GPIO49";

sci1.$name                 = "SCI_COMMS";
sci1.useInterrupts         = false;
sci1.sci.$assign           = "SCIA";
sci1.sci.sci_rxPin.$assign = "GPIO28";
sci1.sci.sci_txPin.$assign = "GPIO29";

sync.ADCSOCAOutputSelect = ["SYSCTL_ADCSOC_SRC_PWM1SOCA","SYSCTL_ADCSOC_SRC_PWM2SOCA","SYSCTL_ADCSOC_SRC_PWM3SOCA","SYSCTL_ADCSOC_SRC_PWM4SOCA","SYSCTL_ADCSOC_SRC_PWM8SOCA"];
sync.ADCSOCBOutputSelect = ["SYSCTL_ADCSOC_SRC_PWM1SOCB","SYSCTL_ADCSOC_SRC_PWM2SOCB","SYSCTL_ADCSOC_SRC_PWM3SOCB","SYSCTL_ADCSOC_SRC_PWM4SOCB","SYSCTL_ADCSOC_SRC_PWM8SOCB"];

CMD.activateCMD = true;

CMD1.$name                                      = "CMD0";
CMD1.sectionMemory_stack                        = ["RAMM1"];
CMD1.sectionMemory_ramfunc                      = ["FLASH_BANK0_SEC1"];
CMD1.sectionAlignEnable_ramfunc                 = true;
CMD1.sectionRunFromDifferentAddr_ramfunc        = true;
CMD1.sectionAlignEnable_text                    = true;
CMD1.sectionMemory_cinit                        = ["FLASH_BANK0_SEC1"];
CMD1.sectionAlignEnable_cinit                   = true;
CMD1.sectionMemory_switch                       = ["FLASH_BANK0_SEC1"];
CMD1.sectionAlignEnable_switch                  = true;
CMD1.sectionMemory_init_array                   = ["FLASH_BANK0_SEC1"];
CMD1.sectionAlignEnable_init_array              = true;
CMD1.sectionMemory_const                        = ["FLASH_BANK0_SEC4"];
CMD1.sectionAlignEnable_const                   = true;
CMD1.sectionMemory_sysmem                       = ["RAMLS5"];
CMD1.sectionMemory_ovly                         = ["FLASH_BANK0_SEC1"];
CMD1.sectionAlignEnable_ovly                    = true;
CMD1.sectionMemory_binit                        = ["FLASH_BANK0_SEC0"];
CMD1.sectionAlignEnable_binit                   = true;
CMD1.sectionMemory_codestart                    = "0x080000";
CMD1.sectionMemory_text                         = ["FLASH_BANK0_SEC2","FLASH_BANK0_SEC3","FLASH_BANK0_SEC4","FLASH_BANK0_SEC5","FLASH_BANK0_SEC6","FLASH_BANK0_SEC7","FLASH_BANK0_SEC8","FLASH_BANK0_SEC9"];
CMD1.sectionMemory_data                         = ["RAMLS5","RAMLS6","RAMLS7"];
CMD1.sectionMemory_bss                          = ["RAMLS1","RAMLS2","RAMLS3","RAMLS4","RAMLS5","RAMLS6"];
CMD1.sectionRun_ramfunc                         = ["RAMGS3"];
CMD1.userSection.create(2);
CMD1.userSection[0].$name                       = "FPUmathTables";
CMD1.userSection[0].sectionName                 = "FPUmathTables";
CMD1.userSection[0].sectionMemory               = ["FLASH_BANK0_SEC6"];
CMD1.userSection[0].sectionRunFromDifferentAddr = true;
CMD1.userSection[0].sectionRun                  = ["RAMGS1"];
CMD1.userSection[0].sectionAlignEnable          = true;
CMD1.userSection[1].$name                       = "dclfuncs";
CMD1.userSection[1].sectionName                 = "dclfuncs";
CMD1.userSection[1].sectionMemory               = ["FLASH_BANK0_SEC7"];
CMD1.userSection[1].sectionRunFromDifferentAddr = true;
CMD1.userSection[1].sectionAlignEnable          = true;
CMD1.userSection[1].sectionRun                  = ["RAMGS2"];

/**
 * Pinmux solution for unlocked pins/peripherals. This ensures that minor changes to the automatic solver in a future
 * version of the tool will not impact the pinmux you originally saw.  These lines can be completely deleted in order to
 * re-solve from scratch.
 */
analog1.analog.$suggestSolution                           = "ANALOG";
analog1.analog["a0/b15/c15/daca_outPin"].$suggestSolution = "A0/B15/C15/DACA_OUT";
analog1.analog["a1/b7/dacb_outPin"].$suggestSolution      = "A1/B7/DACB_OUT";
analog1.analog["a10/b1/c10Pin"].$suggestSolution          = "A10/B1/C10";
analog1.analog["a12, c5Pin"].$suggestSolution             = "A12, C5";
analog1.analog["a2/b6/c9Pin"].$suggestSolution            = "A2/B6/C9";
analog1.analog["a3, c7/b9Pin"].$suggestSolution           = "A3, C7/B9";
analog1.analog["a4/b8Pin"].$suggestSolution               = "A4/B8";
analog1.analog.a5Pin.$suggestSolution                     = "A5";
analog1.analog.a6Pin.$suggestSolution                     = "A6";
analog1.analog.a9Pin.$suggestSolution                     = "A9";
analog1.analog["b0/c11Pin"].$suggestSolution              = "B0/C11";
analog1.analog.b11Pin.$suggestSolution                    = "B11";
analog1.analog["b2/c6Pin"].$suggestSolution               = "B2/C6";
analog1.analog["b3/vdacPin"].$suggestSolution             = "B3/VDAC";
analog1.analog["b4/c8Pin"].$suggestSolution               = "B4/C8";
analog1.analog.b5Pin.$suggestSolution                     = "B5";
analog1.analog.c1Pin.$suggestSolution                     = "C1";
analog1.analog["c2/b12Pin"].$suggestSolution              = "C2/B12";
analog1.analog["c3/a7Pin"].$suggestSolution               = "C3/A7";
epwm1.epwm.$suggestSolution                               = "EPWM4";
